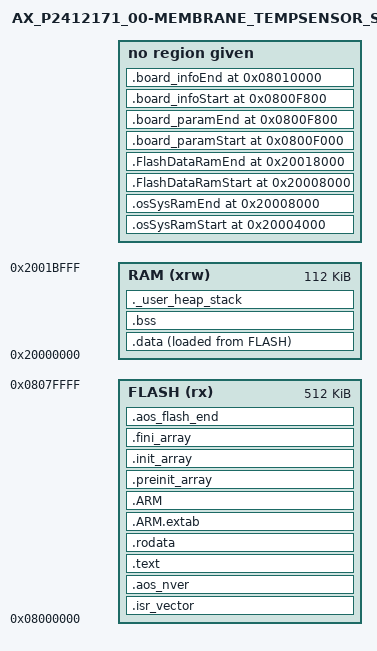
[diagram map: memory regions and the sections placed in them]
/*
******************************************************************************
**
** @file        : LinkerScript.ld
**
** @author      : Auto-generated by STM32CubeIDE
**
** @brief       : Linker script for STM32G491KEUx Device from STM32G4 series
**                      512KBytes FLASH
**                      112KBytes RAM
**
**                Set heap size, stack size and stack location according
**                to application requirements.
**
**                Set memory bank area and size if external memory is used
**
**  Target      : STMicroelectronics STM32
**
**  Distribution: The file is distributed as is, without any warranty
**                of any kind.
**
******************************************************************************
** @attention
**
** Copyright (c) 2024 STMicroelectronics.
** All rights reserved.
**
** This software is licensed under terms that can be found in the LICENSE file
** in the root directory of this software component.
** If no LICENSE file comes with this software, it is provided AS-IS.
**
******************************************************************************
*/

/* Entry Point */
ENTRY(Reset_Handler)

/* Highest address of the user mode stack */
_estack = ORIGIN(RAM) + LENGTH(RAM); /* end of "RAM" Ram type memory */

_Min_Heap_Size = 0x200; /* required amount of heap */
_Min_Stack_Size = 0x400; /* required amount of stack */

/* Memories definition */
MEMORY
{
  RAM    (xrw)    : ORIGIN = 0x20000000,   LENGTH = 112K
  FLASH    (rx)    : ORIGIN = 0x8000000,   LENGTH = 512K
}

/* Sections */
SECTIONS
{
	/* osSysRam is struct + stacks */
	/* Considering 4k of sys structs + 2k of scheduler stack + 1k of user processes stacks means 10k total , 0x2400 */
	_osSysRam_start     = LOADADDR(.osSysRamStart);
	.osSysRamStart 		0x20004000 (NOLOAD): {. = ALIGN(4); KEEP(*(.osSysRamStart))}
	_osSysRam_end       = LOADADDR(.osSysRamEnd);
	.osSysRamEnd 		0x20008000 (NOLOAD): {. = ALIGN(4); KEEP(*(.osSysRamEnd))}
	
	_FlashDataRam_start     = LOADADDR(.FlashDataRamStart);
	.FlashDataRamStart 		0x20008000 (NOLOAD): {. = ALIGN(4); KEEP(*(.FlashDataRamStart))}
	_FlashDataRam_end       = LOADADDR(.FlashDataRamEnd);
	.FlashDataRamEnd 		0x20018000 (NOLOAD): {. = ALIGN(4); KEEP(*(.FlashDataRamEnd))}
	
	_board_params_start = LOADADDR(.board_paramStart);
	.board_paramStart	0x800F000 : {. = ALIGN(4); KEEP(*(.board_paramStart))}
    _board_params_end   = LOADADDR(.board_paramEnd);
	.board_paramEnd 	0x800F800 : {. = ALIGN(4); KEEP(*(.board_paramEnd))}
	
	_board_info_start      = LOADADDR(.board_infoStart);
	.board_infoStart		0x800F800 : {. = ALIGN(4); KEEP(*(.board_infoStart))}
    _board_info_end        = LOADADDR(.board_infoEnd);
	.board_infoEnd  		0x8010000 : {. = ALIGN(4); KEEP(*(.board_infoEnd))}
	
	_fdata_start = LOADADDR(.isr_vector);
	
  /* The startup code into "FLASH" Rom type memory */
  .isr_vector :
  {
    . = ALIGN(4);
    KEEP(*(.isr_vector)) /* Startup code */
    . = ALIGN(4);
  } >FLASH
  .aos_nver :
  {
    . = ALIGN(4);
    KEEP(*(.aos_nver)) /* aos name and version */
    . = ALIGN(4);
  } >FLASH
  /* The program code and other data into "FLASH" Rom type memory */
  .text :
  {
    . = ALIGN(4);
    *(.text)           /* .text sections (code) */
    *(.text*)          /* .text* sections (code) */
    *(.glue_7)         /* glue arm to thumb code */
    *(.glue_7t)        /* glue thumb to arm code */
    *(.eh_frame)

    KEEP (*(.init))
    KEEP (*(.fini))

    . = ALIGN(4);
    _etext = .;        /* define a global symbols at end of code */
  } >FLASH

  /* Constant data into "FLASH" Rom type memory */
  .rodata :
  {
    . = ALIGN(4);
    *(.rodata)         /* .rodata sections (constants, strings, etc.) */
    *(.rodata*)        /* .rodata* sections (constants, strings, etc.) */
    . = ALIGN(4);
  } >FLASH

  .ARM.extab (READONLY) : /* The "READONLY" keyword is only supported in GCC11 and later, remove it if using GCC10 or earlier. */
  {
    . = ALIGN(4);
    *(.ARM.extab* .gnu.linkonce.armextab.*)
    . = ALIGN(4);
  } >FLASH

  .ARM (READONLY) : /* The "READONLY" keyword is only supported in GCC11 and later, remove it if using GCC10 or earlier. */
  {
    . = ALIGN(4);
    __exidx_start = .;
    *(.ARM.exidx*)
    __exidx_end = .;
    . = ALIGN(4);
  } >FLASH

  .preinit_array (READONLY) : /* The "READONLY" keyword is only supported in GCC11 and later, remove it if using GCC10 or earlier. */
  {
    . = ALIGN(4);
    PROVIDE_HIDDEN (__preinit_array_start = .);
    KEEP (*(.preinit_array*))
    PROVIDE_HIDDEN (__preinit_array_end = .);
    . = ALIGN(4);
  } >FLASH

  .init_array (READONLY) : /* The "READONLY" keyword is only supported in GCC11 and later, remove it if using GCC10 or earlier. */
  {
    . = ALIGN(4);
    PROVIDE_HIDDEN (__init_array_start = .);
    KEEP (*(SORT(.init_array.*)))
    KEEP (*(.init_array*))
    PROVIDE_HIDDEN (__init_array_end = .);
    . = ALIGN(4);
  } >FLASH

  .fini_array (READONLY) : /* The "READONLY" keyword is only supported in GCC11 and later, remove it if using GCC10 or earlier. */
  {
    . = ALIGN(4);
    PROVIDE_HIDDEN (__fini_array_start = .);
    KEEP (*(SORT(.fini_array.*)))
    KEEP (*(.fini_array*))
    PROVIDE_HIDDEN (__fini_array_end = .);
    . = ALIGN(4);
  } >FLASH
  
  /* Used by the startup to initialize data */
  _sidata = LOADADDR(.data);

  /* Initialized data sections into "RAM" Ram type memory */
  .data :
  {
    . = ALIGN(4);
    _sdata = .;        /* create a global symbol at data start */
    *(.data)           /* .data sections */
    *(.data*)          /* .data* sections */
    *(.RamFunc)        /* .RamFunc sections */
    *(.RamFunc*)       /* .RamFunc* sections */

    . = ALIGN(4);
    _edata = .;        /* define a global symbol at data end */

  } >RAM AT> FLASH

  /* Uninitialized data section into "RAM" Ram type memory */
  . = ALIGN(4);
  .bss :
  {
    /* This is used by the startup in order to initialize the .bss section */
    _sbss = .;         /* define a global symbol at bss start */
    __bss_start__ = _sbss;
    *(.bss)
    *(.bss*)
    *(COMMON)

    . = ALIGN(4);
    _ebss = .;         /* define a global symbol at bss end */
    __bss_end__ = _ebss;
  } >RAM

  /* User_heap_stack section, used to check that there is enough "RAM" Ram  type memory left */
  ._user_heap_stack :
  {
    . = ALIGN(8);
    PROVIDE ( end = . );
    PROVIDE ( _end = . );
    . = . + _Min_Heap_Size;
    . = . + _Min_Stack_Size;
    . = ALIGN(8);
  } >RAM

  .aos_flash_end :
  {
    . = ALIGN(4);
    KEEP(*(.aos_flash_end)) /* aos name and version */
    . = ALIGN(4);
  } >FLASH


  /* Remove information from the compiler libraries */
  /DISCARD/ :
  {
    libc.a ( * )
    libm.a ( * )
    libgcc.a ( * )
  }

  .ARM.attributes 0 : { *(.ARM.attributes) }
}
